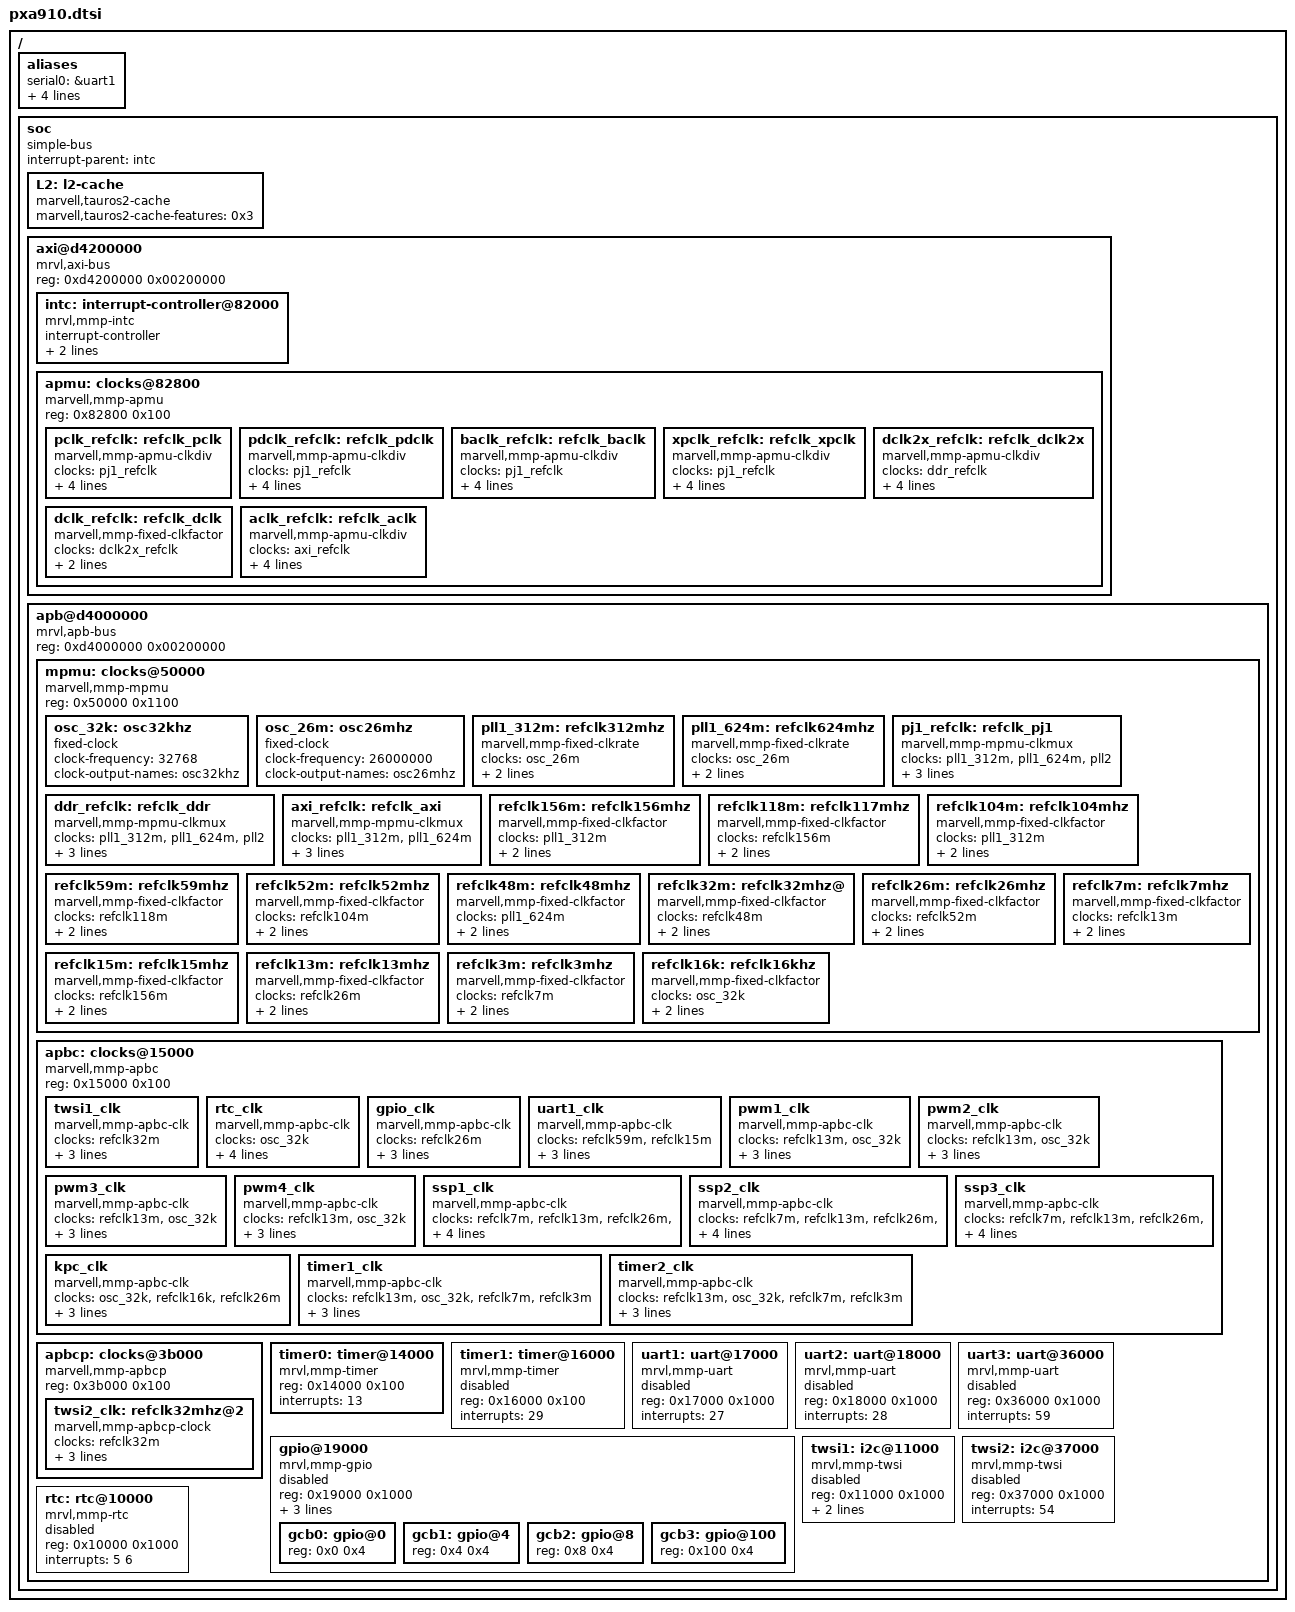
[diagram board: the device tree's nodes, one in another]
/*
 *  Copyright (C) 2012 Marvell Technology Group Ltd.
 *  Author: Haojian Zhuang <haojian.zhuang@marvell.com>
 *
 *  This program is free software; you can redistribute it and/or modify
 *  it under the terms of the GNU General Public License version 2 as
 *  publishhed by the Free Software Foundation.
 */

/include/ "skeleton.dtsi"

/ {
	aliases {
		serial0 = &uart1;
		serial1 = &uart2;
		serial2 = &uart3;
		i2c0 = &twsi1;
		i2c1 = &twsi2;
	};

	soc {
		#address-cells = <1>;
		#size-cells = <1>;
		compatible = "simple-bus";
		interrupt-parent = <&intc>;
		ranges;

		L2: l2-cache {
			compatible = "marvell,tauros2-cache";
			marvell,tauros2-cache-features = <0x3>;
		};

		axi@d4200000 {	/* AXI */
			compatible = "mrvl,axi-bus", "simple-bus";
			#address-cells = <1>;
			#size-cells = <1>;
			reg = <0xd4200000 0x00200000>;
			ranges = <0 0xd4200000 0x00200000>;

			intc: interrupt-controller@82000 {
				compatible = "mrvl,mmp-intc";
				interrupt-controller;
				#interrupt-cells = <1>;
				reg = <0x82000 0x1000>;
				mrvl,intc-nr-irqs = <64>;
			};

			apmu: clocks@82800 {
				compatible = "marvell,mmp-apmu";
				reg = <0x82800 0x100>;

				/*
				 * Processor clocks: pclk, pdclk, baclk, xpclk
				 * DDR Controller clocks: dclk
				 * AXI Fabric clocks: aclk
				 */
				pclk_refclk: refclk_pclk {
					compatible = "marvell,mmp-apmu-clkdiv";
					#clock-cells = <0>;
					clocks = <&pj1_refclk>;
					clock-output-names = "pclk";
					//clock-out-names = "pclk104mhz", "pclk156mhz", "pclk208mhz", "pclk312mhz", "pclk500mhz", "pclk624mhz", "pclk806mhz", "pclk1001mhz";
					marvell,mmp-clock-frequency = <104000000 156000000 208000000 312000000 500500000 624000000 806000000 1001000000>;
					/* register offset & mask */
					marvell,mmp-clk-reg = <0x4 0x7>;
				};
				/* pdclk -- DDR Interface clock */
				pdclk_refclk: refclk_pdclk {
					compatible = "marvell,mmp-apmu-clkdiv";
					#clock-cells = <0>;
					clocks = <&pj1_refclk>;
					clock-output-names = "pdclk";
					marvell,mmp-clock-frequency = <78000000 104000000 156000000 201000000 250250000>;
					/* register offset & mask */
					marvell,mmp-clk-reg = <0x4 0x38>;
				};
				/* baclk -- AXI Fabric Bus Interface clock */
				baclk_refclk: refclk_baclk {
					compatible = "marvell,mmp-apmu-clkdiv";
					#clock-cells = <0>;
					clocks = <&pj1_refclk>;
					clock-output-names = "baclk";
					marvell,mmp-clock-frequency = <78000000 104000000 156000000 201000000 250250000>;
					/* register offset & mask */
					marvell,mmp-clk-reg = <0x4 0x1c0>;
				};
				/* xpclk -- L2 interface clock */
				xpclk_refclk: refclk_xpclk {
					compatible = "marvell,mmp-apmu-clkdiv";
					#clock-cells = <0>;
					clocks = <&pj1_refclk>;
					clock-output-names = "xpclk";
					marvell,mmp-clock-frequency = <104000000 156000000 250250000 312000000 403000000 500500000>;
					/* register offset & mask */
					marvell,mmp-clk-reg = <0x4 0xe00>;
				};
				/* dclk -- DDR Controller clock */
				dclk2x_refclk: refclk_dclk2x {
					compatible = "marvell,mmp-apmu-clkdiv";
					#clock-cells = <0>;
					clocks = <&ddr_refclk>;
					clock-output-names = "dclk2x";
					marvell,mmp-clock-frequency = <208000000 312000000 402000000 500500000>;
					/* register offset & mask */
					marvell,mmp-clk-reg = <0x4 0x7000>;
				};
				dclk_refclk: refclk_dclk {
					compatible = "marvell,mmp-fixed-clkfactor";
					#clock-cells = <0>;
					clocks = <&dclk2x_refclk>;
					clock-output-names = "dclk";
					/* multiple & divider */
					marvell,mmp-fixed-factor = <1 2>;
				};
				/* aclk -- AXI Fabric clock */
				aclk_refclk: refclk_aclk {
					compatible = "marvell,mmp-apmu-clkdiv";
					#clock-cells = <0>;
					clocks = <&axi_refclk>;
					clock-output-names = "aclk";
					marvell,mmp-clock-frequency = <104000000 156000000>;
					/* register offset & mask */
					marvell,mmp-clk-reg = <0x4 0x38000>;
				};
			};
		};

		apb@d4000000 {	/* APB */
			compatible = "mrvl,apb-bus", "simple-bus";
			#address-cells = <1>;
			#size-cells = <1>;
			reg = <0xd4000000 0x00200000>;
			ranges = <0 0xd4000000 0x00200000>;

			mpmu: clocks@50000 {
				compatible = "marvell,mmp-mpmu";
				#address-cells = <1>;
				#size-cells = <1>;
				reg = <0x50000 0x1100>;
				ranges = <0 0x50000 0x1100>;

				osc_32k: osc32khz {
					compatible = "fixed-clock";
					#clock-cells = <0>;
					clock-frequency = <32768>;
					clock-output-names = "osc32khz";
				};
				osc_26m: osc26mhz {
					compatible = "fixed-clock";
					#clock-cells = <0>;
					clock-frequency = <26000000>;
					clock-output-names = "osc26mhz";
				};
				pll1_312m: refclk312mhz {
					compatible = "marvell,mmp-fixed-clkrate";
					#clock-cells = <0>;
					clocks = <&osc_26m>;
					clock-frequency = <312000000>;
					clock-output-names = "refclk312mhz";
				};
				pll1_624m: refclk624mhz {
					compatible = "marvell,mmp-fixed-clkrate";
					#clock-cells = <0>;
					clocks = <&osc_26m>;
					clock-frequency = <624000000>;
					clock-output-names = "refclk624mhz";
				};
				pj1_refclk: refclk_pj1 {
					compatible = "marvell,mmp-mpmu-clkmux";
					#clock-cells = <0>;
					clocks = <&pll1_312m &pll1_624m &pll2>;
					clock-output-names = "refclk_pj1";
					/* register value of each item */
					marvell,mmp-clk-sel = <0 0x20000000 0x40000000>;
					/* register offset & mask */
					marvell,mmp-clk-reg = <0x8 0xe0000000>;
				};
				ddr_refclk: refclk_ddr {
					compatible = "marvell,mmp-mpmu-clkmux";
					#clock-cells = <0>;
					clocks = <&pll1_312m &pll1_624m &pll2>;
					clock-output-names = "refclk_ddr";
					/* register value of each item */
					marvell,mmp-clk-sel = <0 0x00800000 0x01000000>;
					/* register offset & mask */
					marvell,mmp-clk-reg = <0x8 0x01800000>;
				};
				axi_refclk: refclk_axi {
					compatible = "marvell,mmp-mpmu-clkmux";
					#clock-cells = <0>;
					clocks = <&pll1_312m &pll1_624m>;
					clock-output-names = "refclk_axi";
					/* register value of each item */
					marvell,mmp-clk-sel = <0 0x00080000>;
					/* register offset & mask */
					marvell,mmp-clk-reg = <0x8 0x00080000>;
				};
				refclk156m: refclk156mhz {
					compatible = "marvell,mmp-fixed-clkfactor";
					#clock-cells = <0>;
					clocks = <&pll1_312m>;
					clock-output-names = "refclk156mhz";
					/* multiple & divider */
					marvell,mmp-fixed-factor = <1 2>;
				};
				refclk118m: refclk117mhz {
					compatible = "marvell,mmp-fixed-clkfactor";
					#clock-cells = <0>;
					clocks = <&refclk156m>;
					/* 117.9648MHz */
					clock-output-names = "refclk118mhz";
					/* multiple & divider */
					marvell,mmp-fixed-factor = <6144 8125>;
				};
				refclk104m: refclk104mhz {
					compatible = "marvell,mmp-fixed-clkfactor";
					#clock-cells = <0>;
					clocks = <&pll1_312m>;
					clock-output-names = "refclk104mhz";
					/* multiple & divider */
					marvell,mmp-fixed-factor = <1 3>;
				};
				refclk59m: refclk59mhz {
					compatible = "marvell,mmp-fixed-clkfactor";
					#clock-cells = <0>;
					clocks = <&refclk118m>;
					clock-names = "baud_58.98mhz";
					/* 58.9824MHz */
					clock-output-names = "refclk59mhz";
					/* multiple & divider */
					marvell,mmp-fixed-factor = <1 2>;
				};
				refclk52m: refclk52mhz {
					compatible = "marvell,mmp-fixed-clkfactor";
					#clock-cells = <0>;
					clocks = <&refclk104m>;
					clock-output-names = "refclk52mhz";
					/* multiple & divider */
					marvell,mmp-fixed-factor = <1 2>;
				};
				refclk48m: refclk48mhz {
					compatible = "marvell,mmp-fixed-clkfactor";
					#clock-cells = <0>;
					clocks = <&pll1_624m>;
					clock-output-names = "refclk48mhz";
					/* multiple & divider */
					marvell,mmp-fixed-factor = <1 13>;
				};
				refclk32m: refclk32mhz@ {
					compatible = "marvell,mmp-fixed-clkfactor";
					#clock-cells = <0>;
					clocks = <&refclk48m>;
					clock-output-names = "refclk32mhz";
					/* multiple & divider */
					marvell,mmp-fixed-factor = <2 3>;
				};
				refclk26m: refclk26mhz {
					compatible = "marvell,mmp-fixed-clkfactor";
					#clock-cells = <0>;
					clocks = <&refclk52m>;
					clock-output-names = "refclk26mhz";
					/* multiple & divider */
					marvell,mmp-fixed-factor = <1 2>;
				};
				refclk15m: refclk15mhz {
					compatible = "marvell,mmp-fixed-clkfactor";
					#clock-cells = <0>;
					clocks = <&refclk156m>;
					clock-names = "baud_14.86mhz";
					/* 14.857MHz */
					clock-output-names = "refclk15mhz";
					/* multiple & divider */
					marvell,mmp-fixed-factor = <2 21>;
				};
				refclk13m: refclk13mhz {
					compatible = "marvell,mmp-fixed-clkfactor";
					#clock-cells = <0>;
					clocks = <&refclk26m>;
					clock-output-names = "refclk13mhz";
					/* multiple & divider */
					marvell,mmp-fixed-factor = <1 2>;
				};
				refclk7m: refclk7mhz {
					compatible = "marvell,mmp-fixed-clkfactor";
					#clock-cells = <0>;
					clocks = <&refclk13m>;
					clock-output-names = "refclk7mhz";
					/* multiple & divider */
					marvell,mmp-fixed-factor = <1 2>;
				};
				refclk3m: refclk3mhz {
					compatible = "marvell,mmp-fixed-clkfactor";
					#clock-cells = <0>;
					clocks = <&refclk7m>;
					clock-output-names = "refclk3mhz";
					/* multiple & divider */
					marvell,mmp-fixed-factor = <1 2>;
				};
				refclk16k: refclk16khz {
					compatible = "marvell,mmp-fixed-clkfactor";
					#clock-cells = <0>;
					clocks = <&osc_32k>;
					clock-output-names = "refclk16khz";
					/* multiple & divider */
					marvell,mmp-fixed-factor = <1 2>;
				};
			};

			apbc: clocks@15000 {
				compatible = "marvell,mmp-apbc";
				#address-cells = <1>;
				#size-cells = <1>;
				reg = <0x15000 0x100>;
				ranges = <0 0x15000 0x100>;

				twsi1_clk: twsi1_clk {
					compatible = "marvell,mmp-apbc-clk";
					#clock-cells = <0>;
					clocks = <&refclk32m>;
					clock-names = "twsi1_clk";
					/* register value of each item */
					marvell,mmp-clk-sel = <0>;
					/* register offset & mask */
					marvell,mmp-clk-reg = <0x2c 0x70>;
					marvell,mmp-clk-delay = <10>;
				};
				rtc_clk: rtc_clk {
					compatible = "marvell,mmp-apbc-clk";
					#clock-cells = <0>;
					clocks = <&osc_32k>;
					clock-names = "rtc_clk";
					marvell,mmp-clk-sel = <0>;
					/* register offset & mask */
					marvell,mmp-clk-reg = <0x28 0x70>;
					marvell,mmp-apbc-power-ctl;
					marvell,mmp-clk-delay = <10>;
				};
				gpio_clk: gpio_clk {
					compatible = "marvell,mmp-apbc-clk";
					#clock-cells = <0>;
					clocks = <&refclk26m>;
					clock-names = "gpio_clk";
					marvell,mmp-clk-sel = <0>;
					/* register offset & mask */
					marvell,mmp-clk-reg = <0x8 0x0>;
					marvell,mmp-clk-delay = <10>;
				};
				uart1_clk: uart1_clk {
					compatible = "marvell,mmp-apbc-clk";
					#clock-cells = <0>;
					clocks = <&refclk59m &refclk15m>;
					clock-names = "uart1_clk";
					/* register value of each item */
					marvell,mmp-clk-sel = <0 0x10>;
					/* register offset & mask */
					marvell,mmp-clk-reg = <0x0 0x70>;
					marvell,mmp-clk-delay = <10>;
				};
				pwm1_clk: pwm1_clk {
					compatible = "marvell,mmp-apbc-clk";
					#clock-cells = <0>;
					clocks = <&refclk13m &osc_32k>;
					clock-names = "pwm1_clk";
					/* register value of each item */
					marvell,mmp-clk-sel = <0 0x10>;
					/* register offset & mask */
					marvell,mmp-clk-reg = <0xc 0x70>;
					marvell,mmp-clk-delay = <10>;
				};
				pwm2_clk: pwm2_clk {
					compatible = "marvell,mmp-apbc-clk";
					#clock-cells = <0>;
					clocks = <&refclk13m &osc_32k>;
					clock-names = "pwm2_clk";
					/* register value of each item */
					marvell,mmp-clk-sel = <0 0x10>;
					/* register offset & mask */
					marvell,mmp-clk-reg = <0x10 0x70>;
					marvell,mmp-clk-delay = <10>;
				};
				pwm3_clk: pwm3_clk {
					compatible = "marvell,mmp-apbc-clk";
					#clock-cells = <0>;
					clocks = <&refclk13m &osc_32k>;
					clock-names = "pwm1_clk";
					/* register value of each item */
					marvell,mmp-clk-sel = <0 0x10>;
					/* register offset & mask */
					marvell,mmp-clk-reg = <0x14 0x70>;
					marvell,mmp-clk-delay = <10>;
				};
				pwm4_clk: pwm4_clk {
					compatible = "marvell,mmp-apbc-clk";
					#clock-cells = <0>;
					clocks = <&refclk13m &osc_32k>;
					clock-names = "pwm1_clk";
					/* register value of each item */
					marvell,mmp-clk-sel = <0 0x10>;
					/* register offset & mask */
					marvell,mmp-clk-reg = <0x18 0x70>;
					marvell,mmp-clk-delay = <10>;
				};
				ssp1_clk: ssp1_clk {
					compatible = "marvell,mmp-apbc-clk";
					#clock-cells = <0>;
					clocks = <&refclk7m &refclk13m &refclk26m &refclk52m>;
					clock-names = "ssp1_clk";
					/* register value of each item */
					marvell,mmp-clk-sel = <0 0x10 0x20 0x30>;
					/* register offset & mask */
					marvell,mmp-clk-reg = <0x1c 0x70>;
					marvell,mmp-clk-delay = <10>;
				};
				ssp2_clk: ssp2_clk {
					compatible = "marvell,mmp-apbc-clk";
					#clock-cells = <0>;
					clocks = <&refclk7m &refclk13m &refclk26m &refclk52m>;
					clock-names = "ssp2_clk";
					/* register value of each item */
					marvell,mmp-clk-sel = <0 0x10 0x20 0x30>;
					/* register offset & mask */
					marvell,mmp-clk-reg = <0x20 0x70>;
					marvell,mmp-clk-delay = <10>;
				};
				ssp3_clk: ssp3_clk {
					compatible = "marvell,mmp-apbc-clk";
					#clock-cells = <0>;
					clocks = <&refclk7m &refclk13m &refclk26m &refclk52m>;
					clock-names = "ssp3_clk";
					/* register value of each item */
					marvell,mmp-clk-sel = <0 0x10 0x20 0x30>;
					/* register offset & mask */
					marvell,mmp-clk-reg = <0x4c 0x70>;
					marvell,mmp-clk-delay = <10>;
				};
				kpc_clk: kpc_clk {
					compatible = "marvell,mmp-apbc-clk";
					#clock-cells = <0>;
					clocks = <&osc_32k &refclk16k &refclk26m>;
					clock-names = "kpc_clk";
					/* register value of each item */
					marvell,mmp-clk-sel = <0 0x10 0x20>;
					/* register offset & mask */
					marvell,mmp-clk-reg = <0x30 0x70>;
					marvell,mmp-clk-delay = <10>;
				};
				timer1_clk: timer1_clk {
					compatible = "marvell,mmp-apbc-clk";
					#clock-cells = <0>;
					clocks = <&refclk13m &osc_32k &refclk7m &refclk3m>;
					clock-names = "timer1_clk";
					/* register value of each item */
					marvell,mmp-clk-sel = <0 0x10 0x20 0x30>;
					/* register offset & mask */
					marvell,mmp-clk-reg = <0x34 0x70>;
					marvell,mmp-clk-delay = <10>;
				};
				timer2_clk: timer2_clk {
					compatible = "marvell,mmp-apbc-clk";
					#clock-cells = <0>;
					clocks = <&refclk13m &osc_32k &refclk7m &refclk3m>;
					clock-names = "timer2_clk";
					/* register value of each item */
					marvell,mmp-clk-sel = <0 0x10 0x20 0x30>;
					/* register offset & mask */
					marvell,mmp-clk-reg = <0x44 0x70>;
					marvell,mmp-clk-delay = <10>;
				};
			};

			apbcp: clocks@3b000 {
				compatible = "marvell,mmp-apbcp";
				#address-cells = <1>;
				#size-cells = <1>;
				reg = <0x3b000 0x100>;
				ranges = <0 0x3b000 0x100>;

				twsi2_clk: refclk32mhz@2 {
					compatible = "marvell,mmp-apbcp-clock";
					#clock-cells = <0>;
					clocks = <&refclk32m>;
					clock-output-names = "twsi2_clk";
					marvell,mmp-clk-sel = <0>;
					/* register offset & mask */
					marvell,mmp-clk-reg = <0x28 0x70>;
				};
			};

			timer0: timer@14000 {
				compatible = "mrvl,mmp-timer";
				reg = <0x14000 0x100>;
				interrupts = <13>;
			};

			timer1: timer@16000 {
				compatible = "mrvl,mmp-timer";
				reg = <0x16000 0x100>;
				interrupts = <29>;
				status = "disabled";
			};

			uart1: uart@17000 {
				compatible = "mrvl,mmp-uart";
				reg = <0x17000 0x1000>;
				interrupts = <27>;
				status = "disabled";
			};

			uart2: uart@18000 {
				compatible = "mrvl,mmp-uart";
				reg = <0x18000 0x1000>;
				interrupts = <28>;
				status = "disabled";
			};

			uart3: uart@36000 {
				compatible = "mrvl,mmp-uart";
				reg = <0x36000 0x1000>;
				interrupts = <59>;
				status = "disabled";
			};

			gpio@19000 {
				compatible = "mrvl,mmp-gpio";
				#address-cells = <1>;
				#size-cells = <1>;
				reg = <0x19000 0x1000>;
				gpio-controller;
				#gpio-cells = <2>;
				interrupts = <49>;
				interrupt-names = "gpio_mux";
				interrupt-controller;
				#interrupt-cells = <1>;
				ranges = <0 0x19000 0x1000>;
				status = "disabled";

				gcb0: gpio@0 {
					reg = <0x0 0x4>;
				};

				gcb1: gpio@4 {
					reg = <0x4 0x4>;
				};

				gcb2: gpio@8 {
					reg = <0x8 0x4>;
				};

				gcb3: gpio@100 {
					reg = <0x100 0x4>;
				};
			};

			twsi1: i2c@11000 {
				compatible = "mrvl,mmp-twsi";
				#address-cells = <1>;
				#size-cells = <0>;
				reg = <0x11000 0x1000>;
				interrupts = <7>;
				mrvl,i2c-fast-mode;
				status = "disabled";
			};

			twsi2: i2c@37000 {
				compatible = "mrvl,mmp-twsi";
				#address-cells = <1>;
				#size-cells = <0>;
				reg = <0x37000 0x1000>;
				interrupts = <54>;
				status = "disabled";
			};

			rtc: rtc@10000 {
				compatible = "mrvl,mmp-rtc";
				reg = <0x10000 0x1000>;
				interrupts = <5 6>;
				interrupt-names = "rtc 1Hz", "rtc alarm";
				status = "disabled";
			};
		};
	};
};
